VERSION ""

NS_ :

BS_:

BU_:

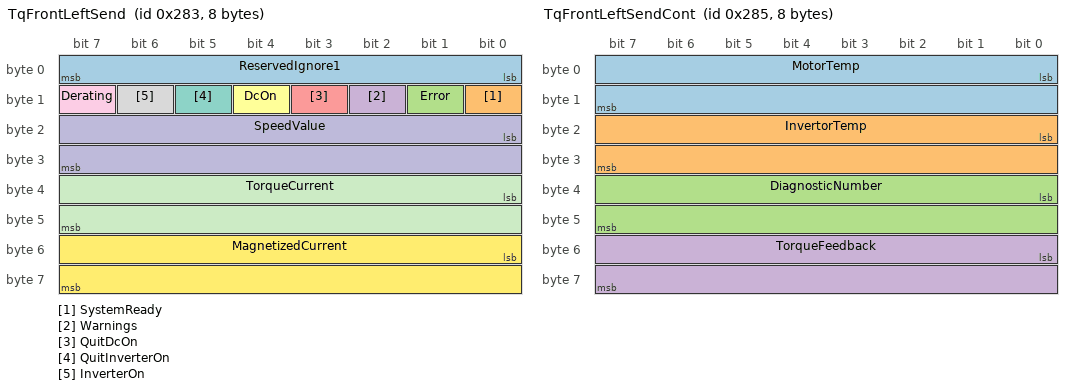
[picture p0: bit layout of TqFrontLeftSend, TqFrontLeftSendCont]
BO_ 643 TqFrontLeftSend: 8 Vector__XXX
 SG_ ReservedIgnore1 : 0|8@1+ (1,0) [0|1] "StatusWord" Vector__XXX
 SG_ SystemReady : 8|1@1+ (1,0) [0|1] "SystemReadySBM" Vector__XXX
 SG_ Error : 9|1@1+ (1,0) [0|1] "" Vector__XXX
 SG_ Warnings : 10|1@1+ (1,0) [0|1] "" Vector__XXX
 SG_ QuitDcOn : 11|1@1+ (1,0) [0|1] "HVActivation" Vector__XXX
 SG_ DcOn : 12|1@1+ (1,0) [0|1] "HVActivationLevel" Vector__XXX
 SG_ QuitInverterOn : 13|1@1+ (1,0) [0|1] "ControllerEnable" Vector__XXX
 SG_ InverterOn : 14|1@1+ (1,0) [0|1] "ControllerEnableAcknow" Vector__XXX
 SG_ Derating : 15|1@1+ (1,0) [0|1] "Nm" Vector__XXX
 SG_ SpeedValue : 16|16@1- (0.01,0) [0|5000] "1/rpm" Vector__XXX
 SG_ TorqueCurrent : 32|16@1- (0.01,0) [0|5000] "Iq" Vector__XXX
 SG_ MagnetizedCurrent : 48|16@1- (0.01,0) [0|5000] "Id" Vector__XXX

BO_ 645 TqFrontLeftSendCont: 8 Vector__XXX
 SG_ MotorTemp : 0|16@1- (0.1,0) [0|500] "C" Vector__XXX
 SG_ InvertorTemp : 16|16@1- (0.1,0) [0|500] "C" Vector__XXX
 SG_ DiagnosticNumber : 32|16@1+ (1,0) [0|20] "" Vector__XXX
 SG_ TorqueFeedback : 48|16@1- (0.1,0) [-30|30] "Nm" Vector__XXX

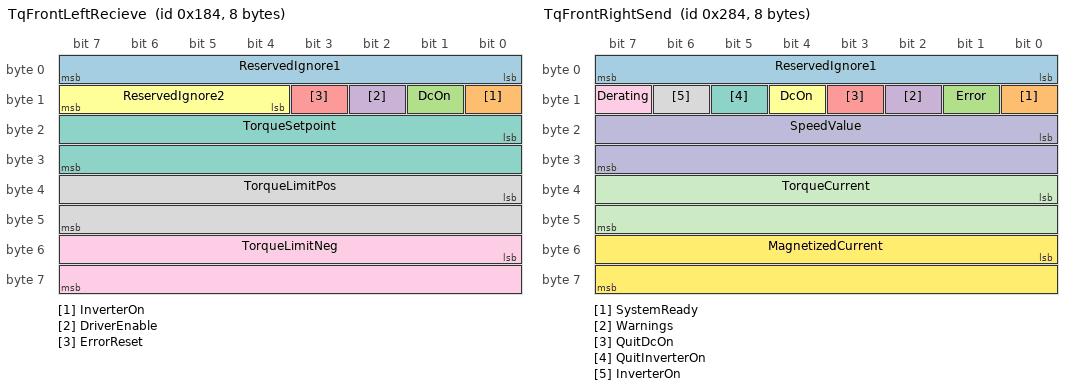
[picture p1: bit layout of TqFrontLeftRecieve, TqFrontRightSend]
BO_ 388 TqFrontLeftRecieve: 8 Vector__XXX
 SG_ ReservedIgnore1 : 0|8@1+ (1,0) [0|1] "" Vector__XXX
 SG_ InverterOn : 8|1@1+ (1,0) [0|1] "" Vector__XXX
 SG_ DcOn : 9|1@1+ (1,0) [0|1] "" Vector__XXX
 SG_ DriverEnable : 10|1@1+ (1,0) [0|1] "" Vector__XXX
 SG_ ErrorReset : 11|1@1+ (1,0) [0|1] "" Vector__XXX
 SG_ ReservedIgnore2 : 12|4@1+ (1,0) [0|1] "" Vector__XXX
 SG_ TorqueSetpoint : 16|16@1- (0.01,0) [-300|300] "%Nm" Vector__XXX
 SG_ TorqueLimitPos : 32|16@1- (0.01,0) [-300|300] "%Nm" Vector__XXX
 SG_ TorqueLimitNeg : 48|16@1- (0.01,0) [-300|300] "%Nm" Vector__XXX

BO_ 644 TqFrontRightSend: 8 Vector__XXX
 SG_ ReservedIgnore1 : 0|8@1+ (1,0) [0|1] "StatusWord" Vector__XXX
 SG_ SystemReady : 8|1@1+ (1,0) [0|1] "SystemReadySBM" Vector__XXX
 SG_ Error : 9|1@1+ (1,0) [0|1] "" Vector__XXX
 SG_ Warnings : 10|1@1+ (1,0) [0|1] "" Vector__XXX
 SG_ QuitDcOn : 11|1@1+ (1,0) [0|1] "HVActivation" Vector__XXX
 SG_ DcOn : 12|1@1+ (1,0) [0|1] "HVActivationLevel" Vector__XXX
 SG_ QuitInverterOn : 13|1@1+ (1,0) [0|1] "ControllerEnable" Vector__XXX
 SG_ InverterOn : 14|1@1+ (1,0) [0|1] "ControllerEnableAcknow" Vector__XXX
 SG_ Derating : 15|1@1+ (1,0) [0|1] "Nm" Vector__XXX
 SG_ SpeedValue : 16|16@1- (0.01,0) [0|5000] "1/rpm" Vector__XXX
 SG_ TorqueCurrent : 32|16@1- (0.01,0) [0|5000] "Iq" Vector__XXX
 SG_ MagnetizedCurrent : 48|16@1- (0.01,0) [0|5000] "Id" Vector__XXX

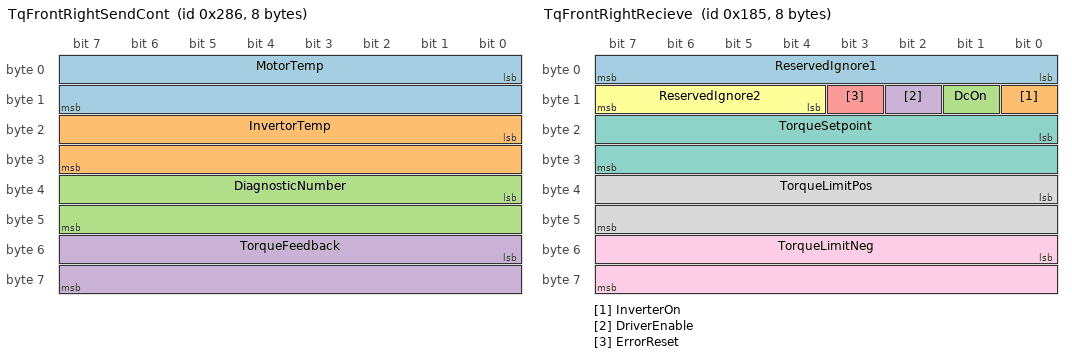
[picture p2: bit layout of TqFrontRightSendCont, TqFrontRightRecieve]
BO_ 646 TqFrontRightSendCont: 8 Vector__XXX
 SG_ MotorTemp : 0|16@1- (0.1,0) [0|500] "C" Vector__XXX
 SG_ InvertorTemp : 16|16@1- (0.1,0) [0|500] "C" Vector__XXX
 SG_ DiagnosticNumber : 32|16@1+ (1,0) [0|20] "" Vector__XXX
 SG_ TorqueFeedback : 48|16@1- (0.1,0) [-30|30] "Nm" Vector__XXX

BO_ 389 TqFrontRightRecieve: 8 Vector__XXX
 SG_ ReservedIgnore1 : 0|8@1+ (1,0) [0|1] "" Vector__XXX
 SG_ InverterOn : 8|1@1+ (1,0) [0|1] "" Vector__XXX
 SG_ DcOn : 9|1@1+ (1,0) [0|1] "" Vector__XXX
 SG_ DriverEnable : 10|1@1+ (1,0) [0|1] "" Vector__XXX
 SG_ ErrorReset : 11|1@1+ (1,0) [0|1] "" Vector__XXX
 SG_ ReservedIgnore2 : 12|4@1+ (1,0) [0|1] "" Vector__XXX
 SG_ TorqueSetpoint : 16|16@1- (0.01,0) [-300|300] "%Nm" Vector__XXX
 SG_ TorqueLimitPos : 32|16@1- (0.01,0) [-300|300] "%Nm" Vector__XXX
 SG_ TorqueLimitNeg : 48|16@1- (0.01,0) [-300|300] "%Nm" Vector__XXX

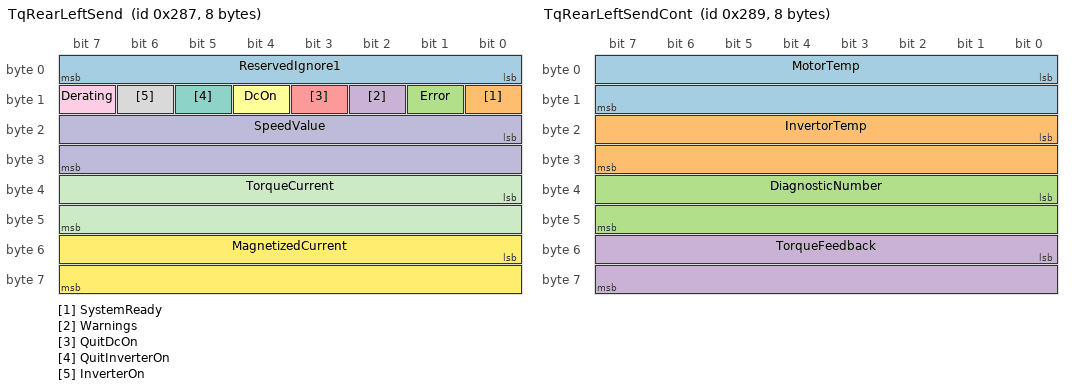
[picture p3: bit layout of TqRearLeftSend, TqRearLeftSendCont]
BO_ 647 TqRearLeftSend: 8 Vector__XXX
 SG_ ReservedIgnore1 : 0|8@1+ (1,0) [0|1] "StatusWord" Vector__XXX
 SG_ SystemReady : 8|1@1+ (1,0) [0|1] "SystemReadySBM" Vector__XXX
 SG_ Error : 9|1@1+ (1,0) [0|1] "" Vector__XXX
 SG_ Warnings : 10|1@1+ (1,0) [0|1] "" Vector__XXX
 SG_ QuitDcOn : 11|1@1+ (1,0) [0|1] "HVActivation" Vector__XXX
 SG_ DcOn : 12|1@1+ (1,0) [0|1] "HVActivationLevel" Vector__XXX
 SG_ QuitInverterOn : 13|1@1+ (1,0) [0|1] "ControllerEnable" Vector__XXX
 SG_ InverterOn : 14|1@1+ (1,0) [0|1] "ControllerEnableAcknow" Vector__XXX
 SG_ Derating : 15|1@1+ (1,0) [0|1] "Nm" Vector__XXX
 SG_ SpeedValue : 16|16@1- (0.01,0) [0|5000] "1/rpm" Vector__XXX
 SG_ TorqueCurrent : 32|16@1- (0.01,0) [0|5000] "Iq" Vector__XXX
 SG_ MagnetizedCurrent : 48|16@1- (0.01,0) [0|5000] "Id" Vector__XXX

BO_ 649 TqRearLeftSendCont: 8 Vector__XXX
 SG_ MotorTemp : 0|16@1- (0.1,0) [0|500] "C" Vector__XXX
 SG_ InvertorTemp : 16|16@1- (0.1,0) [0|500] "C" Vector__XXX
 SG_ DiagnosticNumber : 32|16@1+ (1,0) [0|20] "" Vector__XXX
 SG_ TorqueFeedback : 48|16@1- (0.1,0) [-30|30] "Nm" Vector__XXX

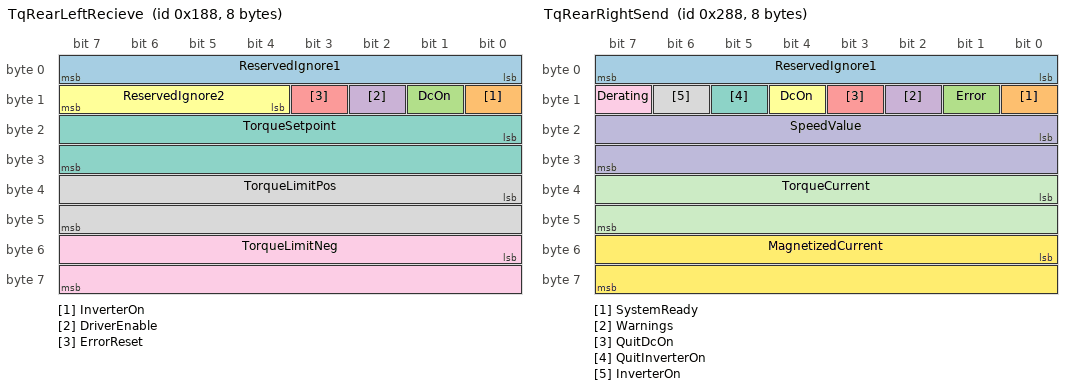
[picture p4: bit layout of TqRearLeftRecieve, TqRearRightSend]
BO_ 392 TqRearLeftRecieve: 8 Vector__XXX
 SG_ ReservedIgnore1 : 0|8@1+ (1,0) [0|1] "" Vector__XXX
 SG_ InverterOn : 8|1@1+ (1,0) [0|1] "" Vector__XXX
 SG_ DcOn : 9|1@1+ (1,0) [0|1] "" Vector__XXX
 SG_ DriverEnable : 10|1@1+ (1,0) [0|1] "" Vector__XXX
 SG_ ErrorReset : 11|1@1+ (1,0) [0|1] "" Vector__XXX
 SG_ ReservedIgnore2 : 12|4@1+ (1,0) [0|1] "" Vector__XXX
 SG_ TorqueSetpoint : 16|16@1- (0.01,0) [-300|300] "%Nm" Vector__XXX
 SG_ TorqueLimitPos : 32|16@1- (0.01,0) [-300|300] "%Nm" Vector__XXX
 SG_ TorqueLimitNeg : 48|16@1- (0.01,0) [-300|300] "%Nm" Vector__XXX

BO_ 648 TqRearRightSend: 8 Vector__XXX
 SG_ ReservedIgnore1 : 0|8@1+ (1,0) [0|1] "StatusWord" Vector__XXX
 SG_ SystemReady : 8|1@1+ (1,0) [0|1] "SystemReadySBM" Vector__XXX
 SG_ Error : 9|1@1+ (1,0) [0|1] "" Vector__XXX
 SG_ Warnings : 10|1@1+ (1,0) [0|1] "" Vector__XXX
 SG_ QuitDcOn : 11|1@1+ (1,0) [0|1] "HVActivation" Vector__XXX
 SG_ DcOn : 12|1@1+ (1,0) [0|1] "HVActivationLevel" Vector__XXX
 SG_ QuitInverterOn : 13|1@1+ (1,0) [0|1] "ControllerEnable" Vector__XXX
 SG_ InverterOn : 14|1@1+ (1,0) [0|1] "ControllerEnableAcknow" Vector__XXX
 SG_ Derating : 15|1@1+ (1,0) [0|1] "Nm" Vector__XXX
 SG_ SpeedValue : 16|16@1- (0.01,0) [0|5000] "1/rpm" Vector__XXX
 SG_ TorqueCurrent : 32|16@1- (0.01,0) [0|5000] "Iq" Vector__XXX
 SG_ MagnetizedCurrent : 48|16@1- (0.01,0) [0|5000] "Id" Vector__XXX

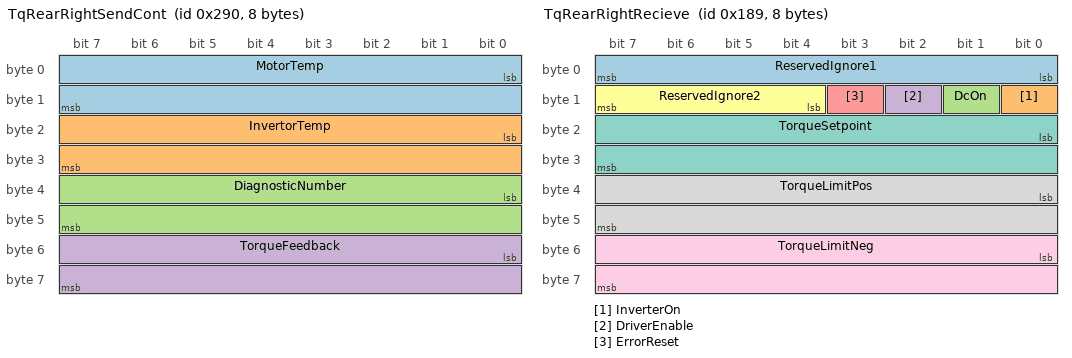
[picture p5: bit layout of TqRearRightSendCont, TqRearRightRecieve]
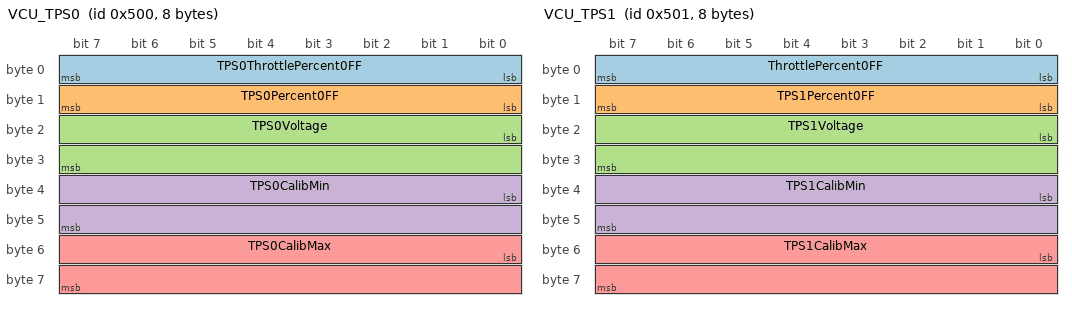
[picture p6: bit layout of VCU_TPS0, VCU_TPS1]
BO_ 656 TqRearRightSendCont: 8 Vector__XXX
 SG_ MotorTemp : 0|16@1- (0.1,0) [0|500] "C" Vector__XXX
 SG_ InvertorTemp : 16|16@1- (0.1,0) [0|500] "C" Vector__XXX
 SG_ DiagnosticNumber : 32|16@1+ (1,0) [0|20] "" Vector__XXX
 SG_ TorqueFeedback : 48|16@1- (0.1,0) [-30|30] "Nm" Vector__XXX

BO_ 393 TqRearRightRecieve: 8 Vector__XXX
 SG_ ReservedIgnore1 : 0|8@1+ (1,0) [0|1] "" Vector__XXX
 SG_ InverterOn : 8|1@1+ (1,0) [0|1] "" Vector__XXX
 SG_ DcOn : 9|1@1+ (1,0) [0|1] "" Vector__XXX
 SG_ DriverEnable : 10|1@1+ (1,0) [0|1] "" Vector__XXX
 SG_ ErrorReset : 11|1@1+ (1,0) [0|1] "" Vector__XXX
 SG_ ReservedIgnore2 : 12|4@1+ (1,0) [0|1] "" Vector__XXX
 SG_ TorqueSetpoint : 16|16@1- (0.01,0) [-300|300] "%Nm" Vector__XXX
 SG_ TorqueLimitPos : 32|16@1- (0.01,0) [-300|300] "%Nm" Vector__XXX
 SG_ TorqueLimitNeg : 48|16@1- (0.01,0) [-300|300] "%Nm" Vector__XXX

 BO_ 1280 VCU_TPS0: 8 VCU
 SG_ TPS0ThrottlePercent0FF : 0|8@1+ (0.392156862746,0) [0|100.00000000023] "%" VCU
 SG_ TPS0Percent0FF : 8|8@1+ (0.392156862746,0) [0|100.00000000023] "%" VCU
 SG_ TPS0Voltage : 16|16@1+ (0.001,0) [0|65.535] "V" VCU
 SG_ TPS0CalibMin : 32|16@1+ (0.001,0) [0|65.535] "V" VCU
 SG_ TPS0CalibMax : 48|16@1+ (0.001,0) [0|65.535] "V" VCU

BO_ 1281 VCU_TPS1: 8 VCU
 SG_ ThrottlePercent0FF : 0|8@1+ (1,0) [0|255] "" VCU
 SG_ TPS1Percent0FF : 8|8@1+ (0.392156862746,0) [0|100.00000000023] "%" VCU
 SG_ TPS1Voltage : 16|16@1+ (0.001,0) [0|65.535] "V" VCU
 SG_ TPS1CalibMin : 32|16@1+ (0.001,0) [0|65.535] "V" VCU
 SG_ TPS1CalibMax : 48|16@1+ (0.001,0) [0|65.535] "V" VCU

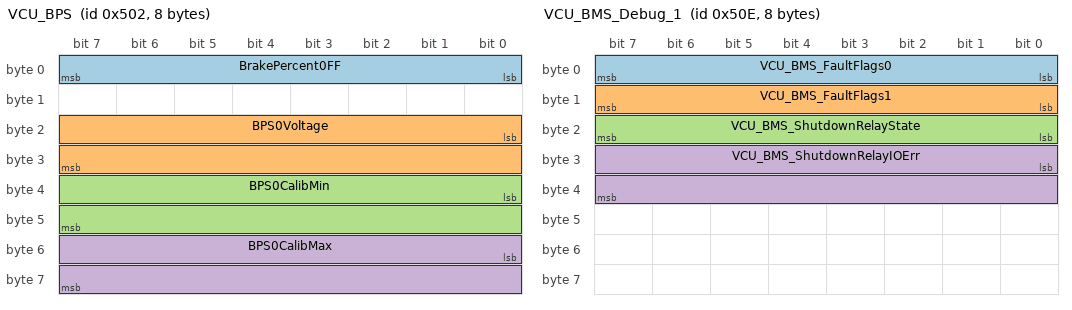
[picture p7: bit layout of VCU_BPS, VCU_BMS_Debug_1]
BO_ 1282 VCU_BPS: 8 VCU
 SG_ BrakePercent0FF : 0|8@1+ (0.392156862746,0) [0|100.00000000023] "%" VCU
 SG_ BPS0Voltage : 16|16@1+ (0.001,0) [0|65.535] "V" VCU
 SG_ BPS0CalibMin : 32|16@1+ (0.001,0) [0|65.535] "V" VCU
 SG_ BPS0CalibMax : 48|16@1+ (0.001,0) [0|65.535] "V" VCU

BO_ 1286 VCU_Safety_Checker: 8 VCU
 SG_ VCU_FAULT_TPS_OutOfRange : 0|1@1+ (1,0) [0|1] "" VCU
 SG_ VCU_FAULT_BPS_OutOfRange : 1|1@1+ (1,0) [0|1] "" VCU
 SG_ VCU_FAULT_TPS_PowerFailure : 2|1@1+ (1,0) [0|1] "" VCU
 SG_ VCU_FAULT_BPS_PowerFailure : 3|1@1+ (1,0) [0|1] "" VCU
 SG_ VCU_FAULT_TPS_SignalFailure : 4|1@1+ (1,0) [0|1] "" VCU
 SG_ VCU_FAULT_BPS_SignalFailure : 5|1@1+ (1,0) [0|1] "" VCU
 SG_ VCU_FAULT_TPS_NotCalibrated : 6|1@1+ (1,0) [0|1] "" VCU
 SG_ VCU_FAULT_BPS_NotCalibrated : 7|1@1+ (1,0) [0|1] "" VCU
 SG_ VCU_FAULT_TPS_OutOfSync : 8|1@1+ (1,0) [0|1] "" VCU
 SG_ VCU_FAULT_TPSBPS_Implausible : 10|1@1+ (1,0) [0|1] "" VCU
 SG_ VCU_FAULT_BSPD_SoftFault : 12|1@1+ (1,0) [0|1] "" VCU
 SG_ VCU_FAULT_LVS_BatteryEmpty : 16|1@1+ (1,0) [0|1] "" VCU
 SG_ VCU_WARNING_LVS_BatteryLow : 32|1@1+ (1,0) [0|1] "" VCU
 SG_ VCU_WARNING_HVIL_OverrideEn : 38|1@1+ (1,0) [0|1] "" VCU
 SG_ VCU_WARNING_SAFETY_BypassEn : 39|1@1+ (1,0) [0|1] "" VCU
 SG_ VCU_NOTICE_HVIL_TermSenseLost : 48|1@1+ (1,0) [0|1] "" VCU
 SG_ VCU_NOTICE_BMS_Over75kW : 52|1@1+ (1,0) [0|1] "" VCU
 SG_ VCU_NOTICE_MCM_Over75kW : 53|1@1+ (1,0) [0|1] "" VCU

BO_ 1287 Low_Voltage: 8 DAQ
 SG_ Voltage : 0|16@1+ (0.001,0) [0|20] "V" VCU

BO_ 1289 MCM_RTD_HVIL: 8 VCU
 SG_ HVIL_Active : 0|16@1+ (1,0) [0|20] "" VCU

BO_ 1290 Torque_Vectoring: 8 mcm

BO_ 1291 AMK_VCU_Debug: 8 mcm
 SG_ Inverter1_StartUpStage : 0|8@1+ (1,0) [0|10] "" VCU
 SG_ Inverter2_StartUpStage : 8|8@1+ (1,0) [0|10] "" VCU

BO_ 1292 DRS_SAS: 8 DAQ
 SG_ Steering_Angle : 0|16@1- (1,0) [-100|100] "Degrees" VCU

BO_ 1294 VCU_BMS_Debug_1: 8 VCU
 SG_ VCU_BMS_FaultFlags0 : 0|8@1+ (1,0) [0|255] "" VCU
 SG_ VCU_BMS_FaultFlags1 : 8|8@1+ (1,0) [0|255] "" VCU
 SG_ VCU_BMS_ShutdownRelayState : 16|8@1+ (1,0) [0|255] "" VCU
 SG_ VCU_BMS_ShutdownRelayIOErr : 24|16@1+ (1,0) [0|255] "" VCU

BO_ 1295 VCU_BMS_Debug_2: 8 VCU
 SG_ VCU_BMS_HighestCellVoltage : 0|16@1+ (1,0) [0|255] "V" VCU
 SG_ VCU_BMS_LowestCellVoltage : 16|16@1+ (1,0) [0|255] "V" VCU
 SG_ VCU_BMS_HighestCellTemp_dC : 32|16@1- (1,0) [-32768|32767] "C" VCU

BO_ 1296 VCU_80kW_Debug: 8 VCU
 SG_ VCU_Safety_Checker_Notices : 32|32@1+ (1,0) [0|1000000] "" VCU

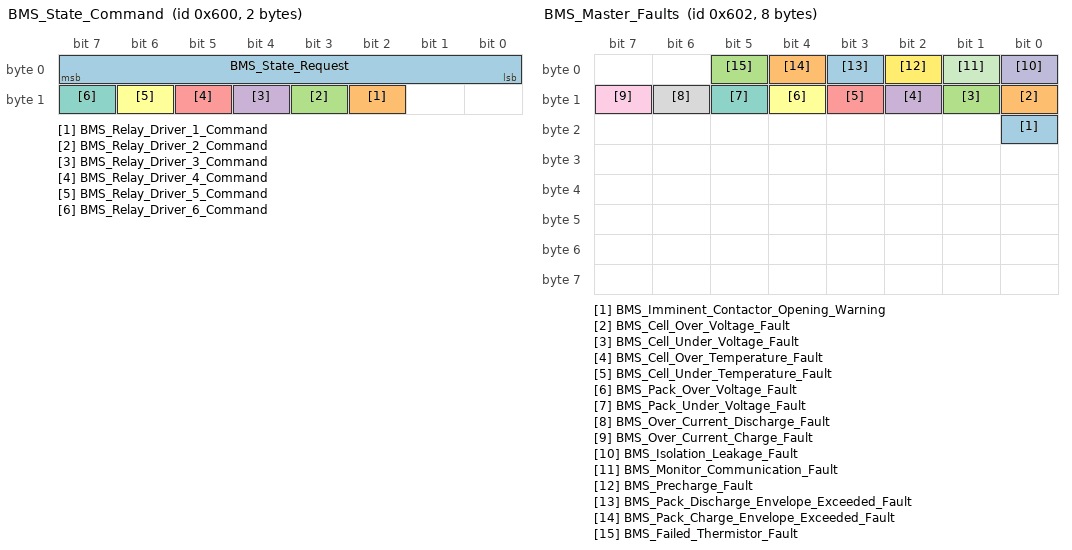
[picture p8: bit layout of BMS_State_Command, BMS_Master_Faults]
BO_ 1536 BMS_State_Command: 2 VCU
 SG_ BMS_State_Request : 0|8@1+ (1,0) [0|4] "" Vector__XXX
 SG_ BMS_Relay_Driver_1_Command : 10|1@1+ (1,0) [0|1] "" Vector__XXX
 SG_ BMS_Relay_Driver_2_Command : 11|1@1+ (1,0) [0|1] "" Vector__XXX
 SG_ BMS_Relay_Driver_3_Command : 12|1@1+ (1,0) [0|1] "" Vector__XXX
 SG_ BMS_Relay_Driver_4_Command : 13|1@1+ (1,0) [0|1] "" Vector__XXX
 SG_ BMS_Relay_Driver_5_Command : 14|1@1+ (1,0) [0|1] "" Vector__XXX
 SG_ BMS_Relay_Driver_6_Command : 15|1@1+ (1,0) [0|1] "" Vector__XXX

BO_ 1538 BMS_Master_Faults: 8 BMS1000M
 SG_ BMS_Imminent_Contactor_Opening_Warning : 16|1@1+ (1,0) [0|1] "" Vector__XXX
 SG_ BMS_Cell_Over_Voltage_Fault : 8|1@1+ (1,0) [0|1] "" Vector__XXX
 SG_ BMS_Cell_Under_Voltage_Fault : 9|1@1+ (1,0) [0|1] "" Vector__XXX
 SG_ BMS_Cell_Over_Temperature_Fault : 10|1@1+ (1,0) [0|1] "" Vector__XXX
 SG_ BMS_Cell_Under_Temperature_Fault : 11|1@1+ (1,0) [0|1] "" Vector__XXX
 SG_ BMS_Pack_Over_Voltage_Fault : 12|1@1+ (1,0) [0|1] "" Vector__XXX
 SG_ BMS_Pack_Under_Voltage_Fault : 13|1@1+ (1,0) [0|1] "" Vector__XXX
 SG_ BMS_Over_Current_Discharge_Fault : 14|1@1+ (1,0) [0|1] "" Vector__XXX
 SG_ BMS_Over_Current_Charge_Fault : 15|1@1+ (1,0) [0|1] "" Vector__XXX
 SG_ BMS_Isolation_Leakage_Fault : 0|1@1+ (1,0) [0|1] "" Vector__XXX
 SG_ BMS_Monitor_Communication_Fault : 1|1@1+ (1,0) [0|1] "" Vector__XXX
 SG_ BMS_Precharge_Fault : 2|1@1+ (1,0) [0|1] "" Vector__XXX
 SG_ BMS_Pack_Discharge_Envelope_Exceeded_Fault : 3|1@1+ (1,0) [0|1] "" Vector__XXX
 SG_ BMS_Pack_Charge_Envelope_Exceeded_Fault : 4|1@1+ (1,0) [0|1] "" Vector__XXX
 SG_ BMS_Failed_Thermistor_Fault : 5|1@1+ (1,0) [0|1] "" Vector__XXX

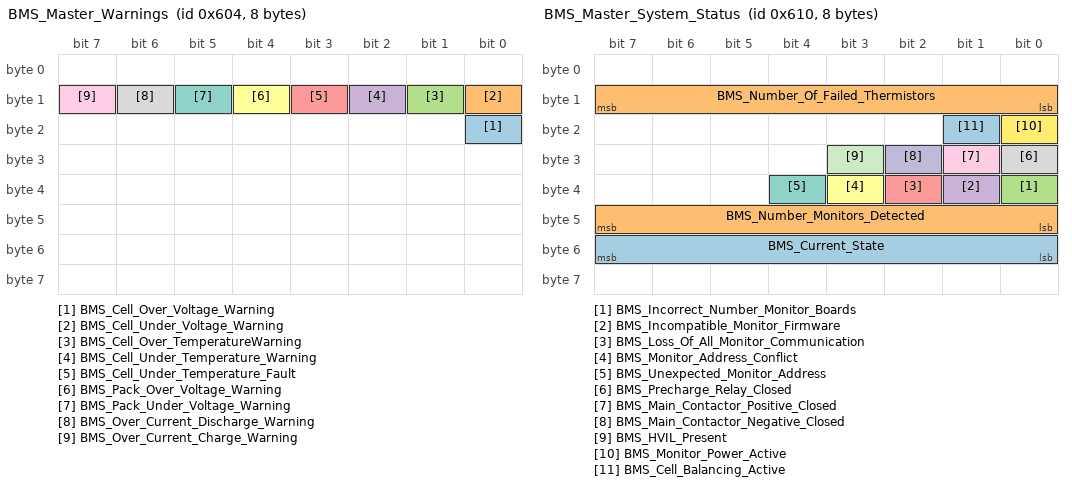
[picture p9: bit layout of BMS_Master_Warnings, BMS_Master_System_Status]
BO_ 1540 BMS_Master_Warnings: 8 BMS1000M
 SG_ BMS_Cell_Over_Voltage_Warning : 16|1@1+ (1,0) [0|1] "" Vector__XXX
 SG_ BMS_Cell_Under_Voltage_Warning : 8|1@1+ (1,0) [0|1] "" Vector__XXX
 SG_ BMS_Cell_Over_TemperatureWarning : 9|1@1+ (1,0) [0|1] "" Vector__XXX
 SG_ BMS_Cell_Under_Temperature_Warning : 10|1@1+ (1,0) [0|1] "" Vector__XXX
 SG_ BMS_Cell_Under_Temperature_Fault : 11|1@1+ (1,0) [0|1] "" Vector__XXX
 SG_ BMS_Pack_Over_Voltage_Warning : 12|1@1+ (1,0) [0|1] "" Vector__XXX
 SG_ BMS_Pack_Under_Voltage_Warning : 13|1@1+ (1,0) [0|1] "" Vector__XXX
 SG_ BMS_Over_Current_Discharge_Warning : 14|1@1+ (1,0) [0|1] "" Vector__XXX
 SG_ BMS_Over_Current_Charge_Warning : 15|1@1+ (1,0) [0|1] "" Vector__XXX

BO_ 1552 BMS_Master_System_Status: 8 BMS1000M
 SG_ BMS_Current_State : 48|8@1+ (1,0) [0|6] "" Vector__XXX
 SG_ BMS_Number_Monitors_Detected : 40|8@1+ (1,0) [0|255] "" Vector__XXX
 SG_ BMS_Incorrect_Number_Monitor_Boards : 32|1@1+ (1,0) [0|1] "" Vector__XXX
 SG_ BMS_Incompatible_Monitor_Firmware : 33|1@1+ (1,0) [0|1] "" Vector__XXX
 SG_ BMS_Loss_Of_All_Monitor_Communication : 34|1@1+ (1,0) [0|1] "" Vector__XXX
 SG_ BMS_Monitor_Address_Conflict : 35|1@1+ (1,0) [0|1] "" Vector__XXX
 SG_ BMS_Unexpected_Monitor_Address : 36|1@1+ (1,0) [0|1] "" Vector__XXX
 SG_ BMS_Precharge_Relay_Closed : 24|1@1+ (1,0) [0|1] "" Vector__XXX
 SG_ BMS_Main_Contactor_Positive_Closed : 25|1@1+ (1,0) [0|1] "" Vector__XXX
 SG_ BMS_Main_Contactor_Negative_Closed : 26|1@1+ (1,0) [0|1] "" Vector__XXX
 SG_ BMS_HVIL_Present : 27|1@1+ (1,0) [0|1] "" Vector__XXX
 SG_ BMS_Monitor_Power_Active : 16|1@1+ (1,0) [0|1] "" Vector__XXX
 SG_ BMS_Cell_Balancing_Active : 17|1@1+ (1,0) [0|1] "" Vector__XXX
 SG_ BMS_Number_Of_Failed_Thermistors : 8|8@1+ (1,0) [0|255] "" Vector__XXX

BO_ 1553 BMS_Pack_Safe_OE: 8 BMS1000M
 SG_ BMS_Charger_Constant_Voltage_Setpoint : 32|16@1+ (0.1,0) [0|1000] "V" Vector__XXX
 SG_ BMS_Maximum_Discharge_Current_Allowed : 16|16@1+ (0.1,0) [0|2500] "A" Vector__XXX
 SG_ BMS_Maximum_Charge_Current_Allowed : 0|16@1+ (0.1,0) [0|2500] "A" Vector__XXX

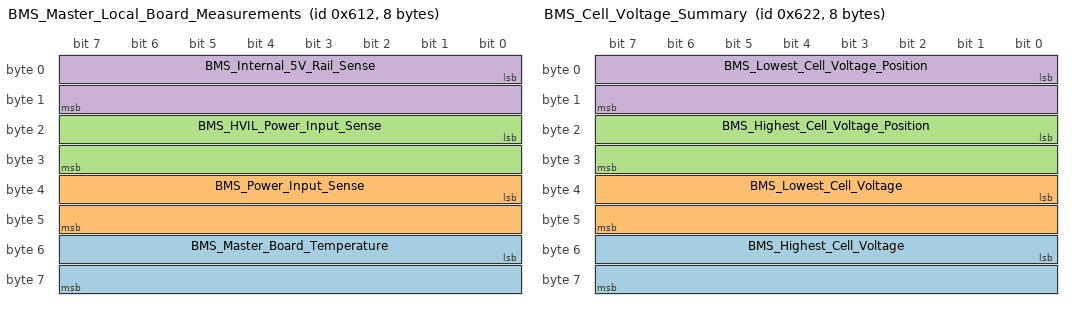
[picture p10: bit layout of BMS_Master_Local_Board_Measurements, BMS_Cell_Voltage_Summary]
BO_ 1554 BMS_Master_Local_Board_Measurements: 8 BMS1000M
 SG_ BMS_Master_Board_Temperature : 48|16@1- (0.1,0) [-50|150] "DegC" Vector__XXX
 SG_ BMS_Power_Input_Sense : 32|16@1+ (0.001,0) [0|36] "V" Vector__XXX
 SG_ BMS_HVIL_Power_Input_Sense : 16|16@1+ (0.001,0) [0|36] "V" Vector__XXX
 SG_ BMS_Internal_5V_Rail_Sense : 0|16@1+ (0.001,0) [0|7.5] "V" Vector__XXX

BO_ 1568 BMS_Pack_Level_Measurements_1: 8 BMS1000M
 SG_ BMS_Pack_Voltage : 32|32@1+ (0.001,0) [0|1500] "V" Vector__XXX
 SG_ BMS_Pack_Current : 0|32@1- (0.001,0) [-2500|2500] "A" Vector__XXX

BO_ 1569 BMS_Pack_Level_Measurements_2: 8 BMS1000M
 SG_ BMS_State_Of_Charge : 48|16@1+ (0.1,0) [0|100] "%" Vector__XXX
 SG_ BMS_State_Of_Health : 32|16@1+ (0.1,0) [0|100] "%" Vector__XXX
 SG_ BMS_Amp_Hours_Remaining : 16|16@1+ (0.1,0) [0|6000] "Ah" Vector__XXX

BO_ 1570 BMS_Cell_Voltage_Summary: 8 BMS1000M
 SG_ BMS_Highest_Cell_Voltage : 48|16@1+ (0.001,0) [0|5] "V" Vector__XXX
 SG_ BMS_Lowest_Cell_Voltage : 32|16@1+ (0.001,0) [0|5] "V" Vector__XXX
 SG_ BMS_Highest_Cell_Voltage_Position : 16|16@1+ (1,0) [0|500] "" Vector__XXX
 SG_ BMS_Lowest_Cell_Voltage_Position : 0|16@1+ (1,0) [0|500] "" Vector__XXX

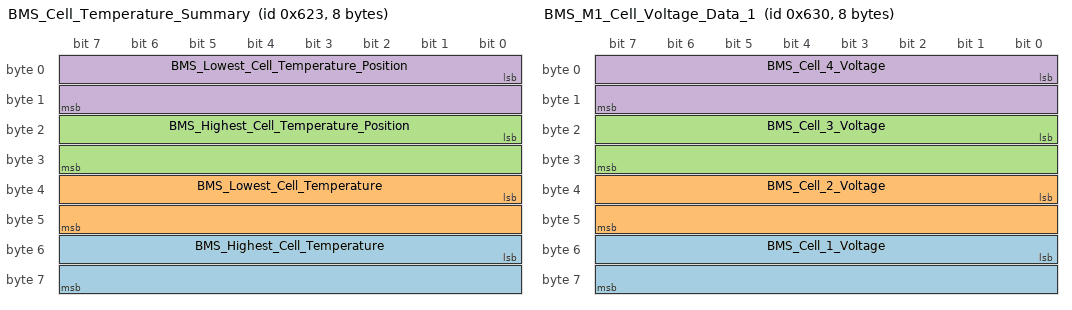
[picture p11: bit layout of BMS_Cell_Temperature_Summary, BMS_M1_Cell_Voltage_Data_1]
BO_ 1571 BMS_Cell_Temperature_Summary: 8 BMS1000M
 SG_ BMS_Highest_Cell_Temperature : 48|16@1- (0.1,0) [-50|150] "DegC" Vector__XXX
 SG_ BMS_Lowest_Cell_Temperature : 32|16@1- (0.1,0) [-50|150] "DegC" Vector__XXX
 SG_ BMS_Highest_Cell_Temperature_Position : 16|16@1+ (1,0) [0|500] "" Vector__XXX
 SG_ BMS_Lowest_Cell_Temperature_Position : 0|16@1+ (1,0) [0|500] "" Vector__XXX

BO_ 1788 BMS_Configuration_Information: 8 BMS1000M
 SG_ BMS_Number_Of_Cells_Configured : 16|16@1+ (1,0) [0|500] "" Vector__XXX
 SG_ BMS_Number_Of_Thermistors_Configured : 0|16@1+ (1,0) [0|500] "" Vector__XXX

BO_ 1790 BMS_Firmware_Version_Information: 8 BMS1000M
 SG_ BMS_Major_Version_Number : 16|8@1+ (1,0) [0|100] "" Vector__XXX
 SG_ BMS_Minor_Version_Number : 8|8@1+ (1,0) [0|100] "" Vector__XXX
 SG_ BMS_Revision_Number : 0|8@1+ (1,0) [0|200] "" Vector__XXX

BO_ 1572 BMS_Pack_Level_Measurements_3: 8 BMS1000M
 SG_ BMS_Sum_Of_Cells_Voltage : 32|32@1+ (0.001,0) [0|1500] "V" Vector__XXX
 SG_ BMS_Precharge_Voltage : 0|32@1+ (0.001,0) [0|1500] "V" Vector__XXX

BO_ 1584 BMS_M1_Cell_Voltage_Data_1: 8 BMS1000M
 SG_ BMS_Cell_1_Voltage : 48|16@1+ (0.001,0) [0|6] "V" Vector__XXX
 SG_ BMS_Cell_2_Voltage : 32|16@1+ (0.001,0) [0|6] "V" Vector__XXX
 SG_ BMS_Cell_3_Voltage : 16|16@1+ (0.001,0) [0|6] "V" Vector__XXX
 SG_ BMS_Cell_4_Voltage : 0|16@1+ (0.001,0) [0|6] "V" Vector__XXX

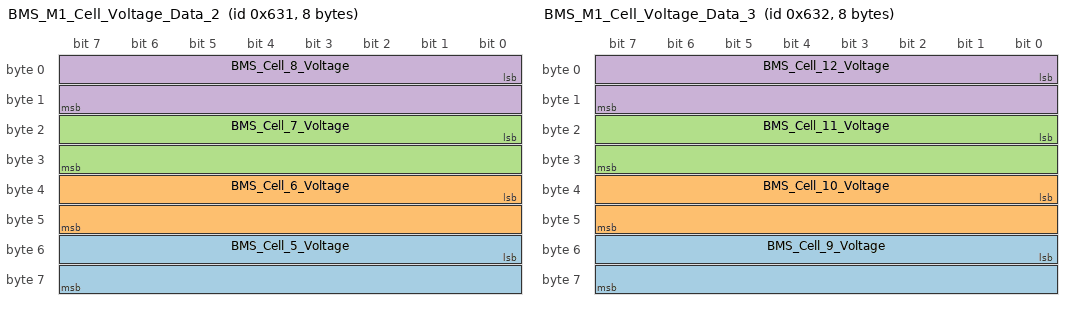
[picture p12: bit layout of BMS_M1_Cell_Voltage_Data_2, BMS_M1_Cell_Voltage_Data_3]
BO_ 1585 BMS_M1_Cell_Voltage_Data_2: 8 BMS1000M
 SG_ BMS_Cell_5_Voltage : 48|16@1+ (0.001,0) [0|6] "V" Vector__XXX
 SG_ BMS_Cell_6_Voltage : 32|16@1+ (0.001,0) [0|6] "V" Vector__XXX
 SG_ BMS_Cell_7_Voltage : 16|16@1+ (0.001,0) [0|6] "V" Vector__XXX
 SG_ BMS_Cell_8_Voltage : 0|16@1+ (0.001,0) [0|6] "V" Vector__XXX

BO_ 1586 BMS_M1_Cell_Voltage_Data_3: 8 BMS1000M
 SG_ BMS_Cell_9_Voltage : 48|16@1+ (0.001,0) [0|6] "V" Vector__XXX
 SG_ BMS_Cell_10_Voltage : 32|16@1+ (0.001,0) [0|6] "V" Vector__XXX
 SG_ BMS_Cell_11_Voltage : 16|16@1+ (0.001,0) [0|6] "V" Vector__XXX
 SG_ BMS_Cell_12_Voltage : 0|16@1+ (0.001,0) [0|6] "V" Vector__XXX

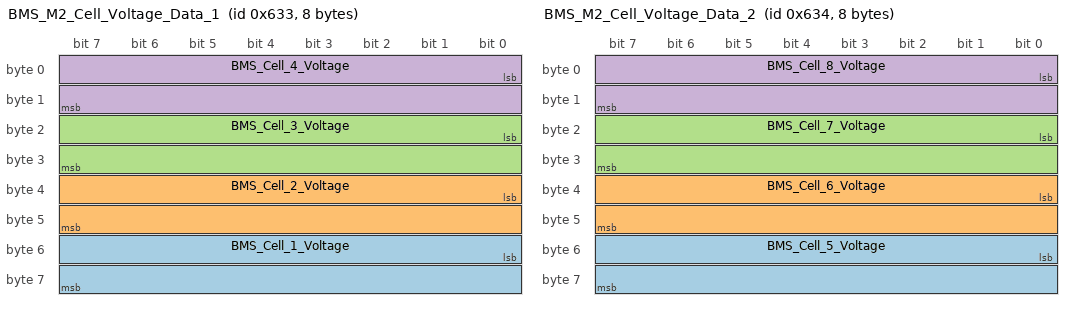
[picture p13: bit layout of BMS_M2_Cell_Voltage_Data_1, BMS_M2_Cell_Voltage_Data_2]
BO_ 1587 BMS_M2_Cell_Voltage_Data_1: 8 BMS1000M
 SG_ BMS_Cell_1_Voltage : 48|16@1+ (0.001,0) [0|6] "C" Vector__XXX
 SG_ BMS_Cell_2_Voltage : 32|16@1+ (0.001,0) [0|6] "C" Vector__XXX
 SG_ BMS_Cell_3_Voltage : 16|16@1+ (0.001,0) [0|6] "C" Vector__XXX
 SG_ BMS_Cell_4_Voltage : 0|16@1+ (0.001,0) [0|6] "C" Vector__XXX

BO_ 1588 BMS_M2_Cell_Voltage_Data_2: 8 BMS1000M
 SG_ BMS_Cell_5_Voltage : 48|16@1+ (0.001,0) [0|6] "V" Vector__XXX
 SG_ BMS_Cell_6_Voltage : 32|16@1+ (0.001,0) [0|6] "V" Vector__XXX
 SG_ BMS_Cell_7_Voltage : 16|16@1+ (0.001,0) [0|6] "V" Vector__XXX
 SG_ BMS_Cell_8_Voltage : 0|16@1+ (0.001,0) [0|6] "V" Vector__XXX

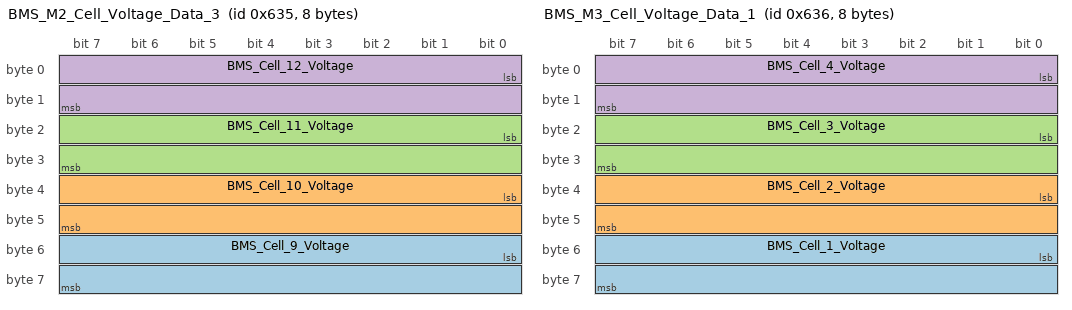
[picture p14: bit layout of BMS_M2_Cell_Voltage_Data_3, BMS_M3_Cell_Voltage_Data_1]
BO_ 1589 BMS_M2_Cell_Voltage_Data_3: 8 BMS1000M
 SG_ BMS_Cell_9_Voltage : 48|16@1+ (0.001,0) [0|6] "V" Vector__XXX
 SG_ BMS_Cell_10_Voltage : 32|16@1+ (0.001,0) [0|6] "V" Vector__XXX
 SG_ BMS_Cell_11_Voltage : 16|16@1+ (0.001,0) [0|6] "V" Vector__XXX
 SG_ BMS_Cell_12_Voltage : 0|16@1+ (0.001,0) [0|6] "V" Vector__XXX

BO_ 1590 BMS_M3_Cell_Voltage_Data_1: 8 BMS1000M
 SG_ BMS_Cell_1_Voltage : 48|16@1+ (0.001,0) [0|6] "V" Vector__XXX
 SG_ BMS_Cell_2_Voltage : 32|16@1+ (0.001,0) [0|6] "V" Vector__XXX
 SG_ BMS_Cell_3_Voltage : 16|16@1+ (0.001,0) [0|6] "V" Vector__XXX
 SG_ BMS_Cell_4_Voltage : 0|16@1+ (0.001,0) [0|6] "V" Vector__XXX

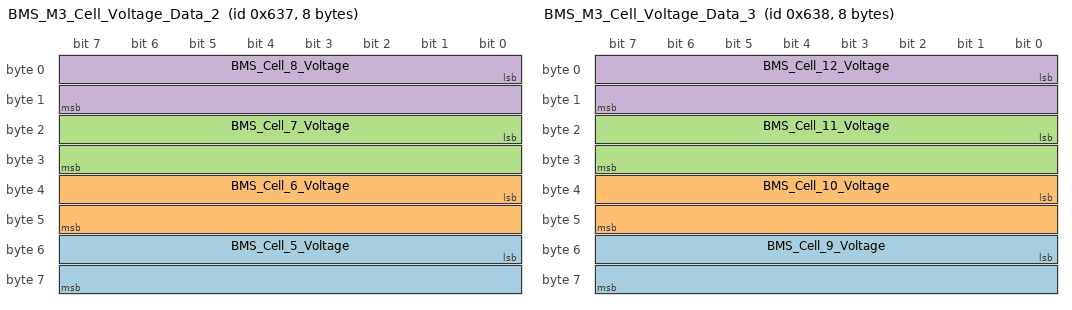
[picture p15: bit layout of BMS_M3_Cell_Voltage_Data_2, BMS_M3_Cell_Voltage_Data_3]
BO_ 1591 BMS_M3_Cell_Voltage_Data_2: 8 BMS1000M
 SG_ BMS_Cell_5_Voltage : 48|16@1+ (0.001,0) [0|6] "V" Vector__XXX
 SG_ BMS_Cell_6_Voltage : 32|16@1+ (0.001,0) [0|6] "V" Vector__XXX
 SG_ BMS_Cell_7_Voltage : 16|16@1+ (0.001,0) [0|6] "V" Vector__XXX
 SG_ BMS_Cell_8_Voltage : 0|16@1+ (0.001,0) [0|6] "V" Vector__XXX

BO_ 1592 BMS_M3_Cell_Voltage_Data_3: 8 BMS1000M
 SG_ BMS_Cell_9_Voltage : 48|16@1+ (0.001,0) [0|6] "V" Vector__XXX
 SG_ BMS_Cell_10_Voltage : 32|16@1+ (0.001,0) [0|6] "V" Vector__XXX
 SG_ BMS_Cell_11_Voltage : 16|16@1+ (0.001,0) [0|6] "V" Vector__XXX
 SG_ BMS_Cell_12_Voltage : 0|16@1+ (0.001,0) [0|6] "V" Vector__XXX

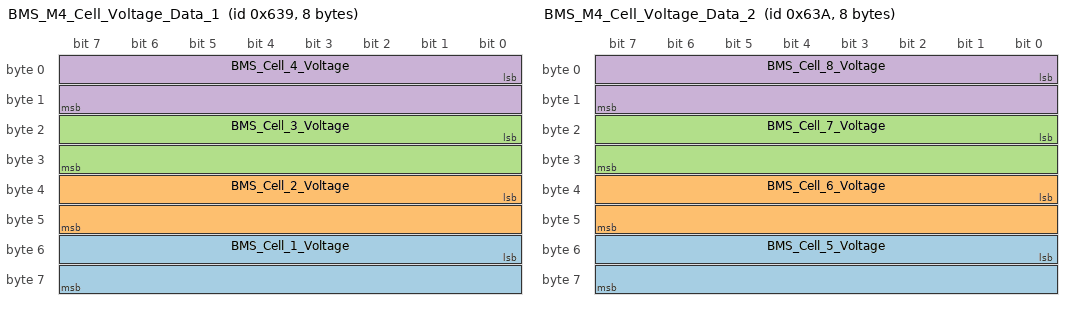
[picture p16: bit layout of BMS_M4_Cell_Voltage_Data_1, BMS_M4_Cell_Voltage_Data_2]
BO_ 1593 BMS_M4_Cell_Voltage_Data_1: 8 BMS1000M
 SG_ BMS_Cell_1_Voltage : 48|16@1+ (0.001,0) [0|6] "V" Vector__XXX
 SG_ BMS_Cell_2_Voltage : 32|16@1+ (0.001,0) [0|6] "V" Vector__XXX
 SG_ BMS_Cell_3_Voltage : 16|16@1+ (0.001,0) [0|6] "V" Vector__XXX
 SG_ BMS_Cell_4_Voltage : 0|16@1+ (0.001,0) [0|6] "V" Vector__XXX

BO_ 1594 BMS_M4_Cell_Voltage_Data_2: 8 BMS1000M
 SG_ BMS_Cell_5_Voltage : 48|16@1+ (0.001,0) [0|6] "V" Vector__XXX
 SG_ BMS_Cell_6_Voltage : 32|16@1+ (0.001,0) [0|6] "V" Vector__XXX
 SG_ BMS_Cell_7_Voltage : 16|16@1+ (0.001,0) [0|6] "V" Vector__XXX
 SG_ BMS_Cell_8_Voltage : 0|16@1+ (0.001,0) [0|6] "V" Vector__XXX

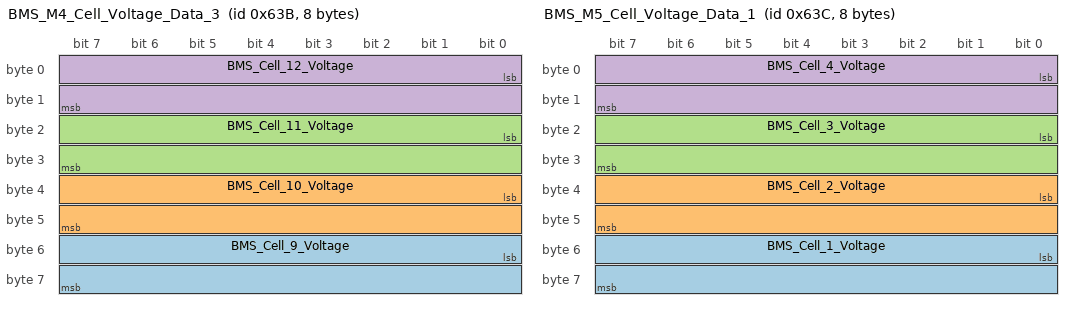
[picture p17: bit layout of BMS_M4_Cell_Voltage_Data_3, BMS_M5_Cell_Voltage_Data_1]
BO_ 1595 BMS_M4_Cell_Voltage_Data_3: 8 BMS1000M
 SG_ BMS_Cell_9_Voltage : 48|16@1+ (0.001,0) [0|6] "V" Vector__XXX
 SG_ BMS_Cell_10_Voltage : 32|16@1+ (0.001,0) [0|6] "V" Vector__XXX
 SG_ BMS_Cell_11_Voltage : 16|16@1+ (0.001,0) [0|6] "V" Vector__XXX
 SG_ BMS_Cell_12_Voltage : 0|16@1+ (0.001,0) [0|6] "V" Vector__XXX

BO_ 1596 BMS_M5_Cell_Voltage_Data_1: 8 BMS1000M
 SG_ BMS_Cell_1_Voltage : 48|16@1+ (0.001,0) [0|6] "V" Vector__XXX
 SG_ BMS_Cell_2_Voltage : 32|16@1+ (0.001,0) [0|6] "V" Vector__XXX
 SG_ BMS_Cell_3_Voltage : 16|16@1+ (0.001,0) [0|6] "V" Vector__XXX
 SG_ BMS_Cell_4_Voltage : 0|16@1+ (0.001,0) [0|6] "V" Vector__XXX

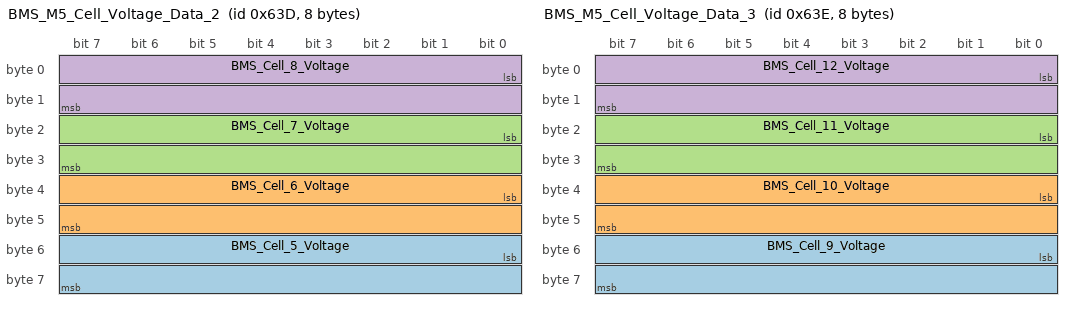
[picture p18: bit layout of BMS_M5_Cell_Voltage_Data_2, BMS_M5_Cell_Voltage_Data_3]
BO_ 1597 BMS_M5_Cell_Voltage_Data_2: 8 BMS1000M
 SG_ BMS_Cell_5_Voltage : 48|16@1+ (0.001,0) [0|6] "V" Vector__XXX
 SG_ BMS_Cell_6_Voltage : 32|16@1+ (0.001,0) [0|6] "V" Vector__XXX
 SG_ BMS_Cell_7_Voltage : 16|16@1+ (0.001,0) [0|6] "V" Vector__XXX
 SG_ BMS_Cell_8_Voltage : 0|16@1+ (0.001,0) [0|6] "V" Vector__XXX

BO_ 1598 BMS_M5_Cell_Voltage_Data_3: 8 BMS1000M
 SG_ BMS_Cell_9_Voltage : 48|16@1+ (0.001,0) [0|6] "V" Vector__XXX
 SG_ BMS_Cell_10_Voltage : 32|16@1+ (0.001,0) [0|6] "V" Vector__XXX
 SG_ BMS_Cell_11_Voltage : 16|16@1+ (0.001,0) [0|6] "V" Vector__XXX
 SG_ BMS_Cell_12_Voltage : 0|16@1+ (0.001,0) [0|6] "V" Vector__XXX

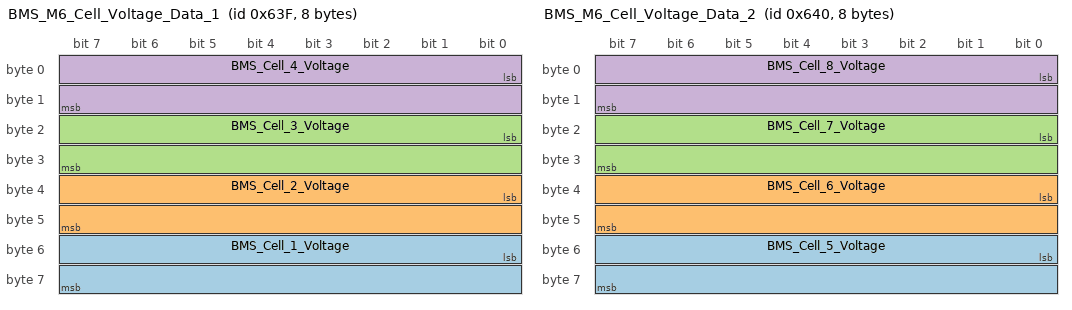
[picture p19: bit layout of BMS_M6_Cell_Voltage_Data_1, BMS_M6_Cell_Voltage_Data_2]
BO_ 1599 BMS_M6_Cell_Voltage_Data_1: 8 BMS1000M
 SG_ BMS_Cell_1_Voltage : 48|16@1+ (0.001,0) [0|6] "V" Vector__XXX
 SG_ BMS_Cell_2_Voltage : 32|16@1+ (0.001,0) [0|6] "V" Vector__XXX
 SG_ BMS_Cell_3_Voltage : 16|16@1+ (0.001,0) [0|6] "V" Vector__XXX
 SG_ BMS_Cell_4_Voltage : 0|16@1+ (0.001,0) [0|6] "V" Vector__XXX

BO_ 1600 BMS_M6_Cell_Voltage_Data_2: 8 BMS1000M
 SG_ BMS_Cell_5_Voltage : 48|16@1+ (0.001,0) [0|6] "V" Vector__XXX
 SG_ BMS_Cell_6_Voltage : 32|16@1+ (0.001,0) [0|6] "V" Vector__XXX
 SG_ BMS_Cell_7_Voltage : 16|16@1+ (0.001,0) [0|6] "V" Vector__XXX
 SG_ BMS_Cell_8_Voltage : 0|16@1+ (0.001,0) [0|6] "V" Vector__XXX

BO_ 1601 BMS_M6_Cell_Voltage_Data_3: 8 BMS1000M
 SG_ BMS_Cell_9_Voltage : 48|16@1+ (0.001,0) [0|6] "V" Vector__XXX
 SG_ BMS_Cell_10_Voltage : 32|16@1+ (0.001,0) [0|6] "V" Vector__XXX
 SG_ BMS_Cell_11_Voltage : 16|16@1+ (0.001,0) [0|6] "V" Vector__XXX
 SG_ BMS_Cell_12_Voltage : 0|16@1+ (0.001,0) [0|6] "V" Vector__XXX

BO_ 1664 BMS_M1_Cell_Temp_Data: 8 BMS1000M
 SG_ BMS_Section_1_Temp : 48|16@1+ (0.1,0) [0|6] "C" Vector__XXX
 SG_ BMS_Section_2_Temp : 32|16@1+ (0.1,0) [0|6] "C" Vector__XXX
 SG_ BMS_Section_3_Temp : 16|16@1+ (0.1,0) [0|6] "C" Vector__XXX
 SG_ BMS_Section_4_Temp : 0|16@1+ (0.1,0) [0|6] "C" Vector__XXX

BO_ 1667 BMS_M2_Cell_Temp_Data: 8 BMS1000M
 SG_ BMS_Section_1_Temp : 48|16@1+ (0.1,0) [0|6] "C" Vector__XXX
 SG_ BMS_Section_2_Temp : 32|16@1+ (0.1,0) [0|6] "C" Vector__XXX
 SG_ BMS_Section_3_Temp : 16|16@1+ (0.1,0) [0|6] "C" Vector__XXX
 SG_ BMS_Section_4_Temp : 0|16@1+ (0.1,0) [0|6] "C" Vector__XXX

BO_ 1670 BMS_M3_Cell_Temp_Data: 8 BMS1000M
 SG_ BMS_Section_1_Temp : 48|16@1+ (0.1,0) [0|6] "C" Vector__XXX
 SG_ BMS_Section_2_Temp : 32|16@1+ (0.1,0) [0|6] "C" Vector__XXX
 SG_ BMS_Section_3_Temp : 16|16@1+ (0.1,0) [0|6] "C" Vector__XXX
 SG_ BMS_Section_4_Temp : 0|16@1+ (0.1,0) [0|6] "C" Vector__XXX

BO_ 1673 BMS_M4_Cell_Temp_Data: 8 BMS1000M
 SG_ BMS_Section_1_Temp : 48|16@1+ (0.1,0) [0|6] "C" Vector__XXX
 SG_ BMS_Section_2_Temp : 32|16@1+ (0.1,0) [0|6] "C" Vector__XXX
 SG_ BMS_Section_3_Temp : 16|16@1+ (0.1,0) [0|6] "C" Vector__XXX
 SG_ BMS_Section_4_Temp : 0|16@1+ (0.1,0) [0|6] "C" Vector__XXX

BO_ 1676 BMS_M5_Cell_Temp_Data: 8 BMS1000M
 SG_ BMS_Section_1_Temp : 48|16@1+ (0.1,0) [0|6] "C" Vector__XXX
 SG_ BMS_Section_2_Temp : 32|16@1+ (0.1,0) [0|6] "C" Vector__XXX
 SG_ BMS_Section_3_Temp : 16|16@1+ (0.1,0) [0|6] "C" Vector__XXX
 SG_ BMS_Section_4_Temp : 0|16@1+ (0.1,0) [0|6] "C" Vector__XXX

BO_ 1679 BMS_M6_Cell_Temp_Data: 8 BMS1000M
 SG_ BMS_Section_1_Temp : 48|16@1+ (0.1,0) [0|6] "C" Vector__XXX
 SG_ BMS_Section_2_Temp : 32|16@1+ (0.1,0) [0|6] "C" Vector__XXX
 SG_ BMS_Section_3_Temp : 16|16@1+ (0.1,0) [0|6] "C" Vector__XXX
 SG_ BMS_Section_4_Temp : 0|16@1+ (0.1,0) [0|6] "C" Vector__XXX

CM_ BO_ 643 "FreeCAN Torque Front Left MCM Send";
CM_ BO_ 645 "FreeCAN Torque Front Left MCM Send";
CM_ SG_ 645 MotorTemp "0,1 C";
CM_ SG_ 645 InvertorTemp "0,1 C";
CM_ SG_ 645 DiagnosticNumber "Diagnostic Numbers";
CM_ BO_ 388 "FreeCAN Torque Front Left MCM Recieve";
CM_ SG_ 388 TorqueSetpoint "Torque Setpoint";
CM_ SG_ 388 TorqueLimitPos "Torque Limitation Positive";
CM_ SG_ 388 TorqueLimitNeg "Torque Limitation Negative";
BA_DEF_ BO_  "VFrameFormat" ENUM  "StandardCAN","ExtendedCAN","reserved","J1939PG";
BA_DEF_  "DatabaseVersion" STRING ;
BA_DEF_  "BusType" STRING ;
BA_DEF_  "ProtocolType" STRING ;
BA_DEF_  "DatabaseCompiler" STRING ;
BA_DEF_DEF_  "VFrameFormat" "J1939PG";
BA_DEF_DEF_  "DatabaseVersion" "DEMO PLUS";
BA_DEF_DEF_  "BusType" "";
BA_DEF_DEF_  "ProtocolType" "";
BA_DEF_DEF_  "DatabaseCompiler" "";
BA_ "ProtocolType" "J1939";
BA_ "BusType" "CAN";
BA_ "DatabaseCompiler" "CSS ELECTRONICS (WWW.CSSELECTRONICS.COM)";
BA_ "DatabaseVersion" "1.0.0";
